# netx90_app register map
File version: 1.0
CPU: CM4 r0p1, little endian, MPU, FPU, 4 interrupt priority bits, 78 interrupts
Registers are 32-bit, read-write, reset 0x0 unless marked. A register's access mark holds for its fields unless they carry their own. Offsets are from the block's base; [hi:lo] are bit positions; {n}, {i} and the like mark numbered series.

## dmac_mux_app
Base 0xFF801000
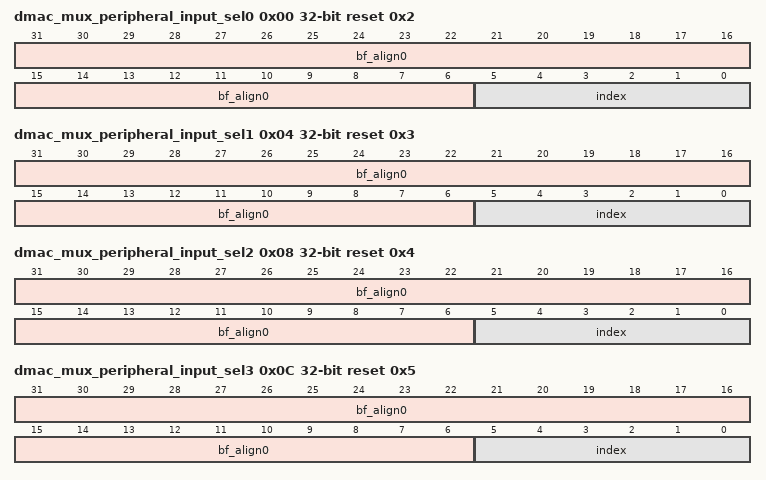
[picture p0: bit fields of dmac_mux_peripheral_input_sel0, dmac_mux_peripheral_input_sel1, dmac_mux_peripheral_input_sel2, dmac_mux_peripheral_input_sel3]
0x00 dmac_mux_peripheral_input_sel0 reset 0x2 (reset mask 0x3F) — Peripheral input select for DMAC input channel 0 This register configures which peripheral should be connected to DMAC's input channel 0. Note: This should not be changed while any of the DMA channels are performing DMA transfers.
  [31:6] bf_align0 — bitField alignment value for aeabi compatibility
  [5:0] index — Index of the peripheral to be connected to DMAC's input channel 0. Default connected peripheral: uart_app_rx { | Number Peripheral 0 uart_rx 1 uart_tx 2 uart_app_rx (default on DMAC input channel 0) 3 uart_app_tx (default on DMAC input channel 1) 4 i2c_app_master (default on DMAC input channel 2) 5 i2c_app_slave (default on DMAC input channel 3) 6 spi0_app_rx (default on DMAC input channel 4) 7 spi0_app_tx (default on DMAC input channel 5) 8 spi1_app_rx 9 spi1_app_tx 10 spi2_app_rx 11 spi2_app_tx 12 sqi0_app_rx 13 sqi0_app_tx 14 sqi1_app_rx 15 sqi1_app_tx 16 uart_xpic_app_rx 17 uart_xpic_app_tx 18 i2c_xpic_app_master 19 i2c_xpic_app_slave 20 spi_xpic_app_rx 21 spi_xpic_app_tx 22 sqi_rx 23 sqi_tx 24 eth_rx 25 eth_tx 26 hash 27 aes_in 28 aes_out 29 no connection 30 - 31 reserved }
0x04 dmac_mux_peripheral_input_sel1 reset 0x3 (reset mask 0x3F) — Peripheral input select for DMAC input channel 1 This register configures which peripheral should be connected to DMAC's input channel 1. Note: This should not be changed while any of the DMA channels are performing DMA transfers.
  [31:6] bf_align0 — bitField alignment value for aeabi compatibility
  [5:0] index — Index of the peripheral to be connected to DMAC's input channel 1. Default connected peripheral: uart_app_tx For a list of available peripheral indices, see dmac_mux_peripheral_input_sel0.
0x08 dmac_mux_peripheral_input_sel2 reset 0x4 (reset mask 0x3F) — Peripheral input select for DMAC input channel 2 This register configures which peripheral should be connected to DMAC's input channel 2. Note: This should not be changed while any of the DMA channels are performing DMA transfers.
  [31:6] bf_align0 — bitField alignment value for aeabi compatibility
  [5:0] index — Index of the peripheral to be connected to DMAC's input channel 2. Default connected peripheral: i2c_app_master For a list of available peripheral indices, see dmac_mux_peripheral_input_sel0.
0x0C dmac_mux_peripheral_input_sel3 reset 0x5 (reset mask 0x3F) — Peripheral input select for DMAC input channel 3 This register configures which peripheral should be connected to DMAC's input channel 3. Note: This should not be changed while any of the DMA channels are performing DMA transfers.
  [31:6] bf_align0 — bitField alignment value for aeabi compatibility
  [5:0] index — Index of the peripheral to be connected to DMAC's input channel 3. Default connected peripheral: i2c_app_slave For a list of available peripheral indices, see dmac_mux_peripheral_input_sel0.
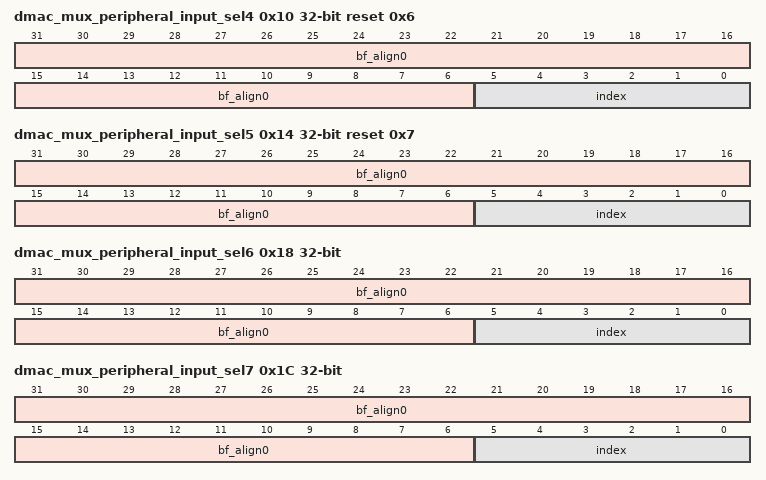
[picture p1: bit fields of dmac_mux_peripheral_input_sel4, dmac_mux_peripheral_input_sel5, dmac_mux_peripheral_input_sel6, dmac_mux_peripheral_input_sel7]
0x10 dmac_mux_peripheral_input_sel4 reset 0x6 (reset mask 0x3F) — Peripheral input select for DMAC input channel 4 This register configures which peripheral should be connected to DMAC's input channel 4. Note: This should not be changed while any of the DMA channels are performing DMA transfers.
  [31:6] bf_align0 — bitField alignment value for aeabi compatibility
  [5:0] index — Index of the peripheral to be connected to DMAC's input channel 4. Default connected peripheral: spi0_app_rx For a list of available peripheral indices, see dmac_mux_peripheral_input_sel0.
0x14 dmac_mux_peripheral_input_sel5 reset 0x7 (reset mask 0x3F) — Peripheral input select for DMAC input channel 5 This register configures which peripheral should be connected to DMAC's input channel 5. Note: This should not be changed while any of the DMA channels are performing DMA transfers.
  [31:6] bf_align0 — bitField alignment value for aeabi compatibility
  [5:0] index — Index of the peripheral to be connected to DMAC's input channel 5. Default connected peripheral: spi0_app_tx For a list of available peripheral indices, see dmac_mux_peripheral_input_sel0.
0x18 dmac_mux_peripheral_input_sel6 (reset mask 0x3F) — Peripheral input select for DMAC input channel 6 This register configures which peripheral should be connected to DMAC's input channel 6. Note: This should not be changed while any of the DMA channels are performing DMA transfers.
  [31:6] bf_align0 — bitField alignment value for aeabi compatibility
  [5:0] index — Index of the peripheral to be connected to DMAC's input channel 6. Default connected peripheral: uart_rx For a list of available peripheral indices, see dmac_mux_peripheral_input_sel0.
0x1C dmac_mux_peripheral_input_sel7 (reset mask 0x3F) — Peripheral input select for DMAC input channel 7 This register configures which peripheral should be connected to DMAC's input channel 7. Note: This should not be changed while any of the DMA channels are performing DMA transfers.
  [31:6] bf_align0 — bitField alignment value for aeabi compatibility
  [5:0] index — Index of the peripheral to be connected to DMAC's input channel 7. Default connected peripheral: uart_rx For a list of available peripheral indices, see dmac_mux_peripheral_input_sel0.
